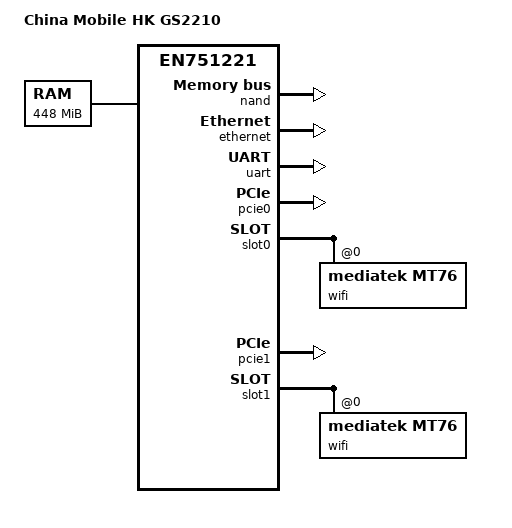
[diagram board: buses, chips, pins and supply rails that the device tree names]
// SPDX-License-Identifier: (GPL-2.0-only OR BSD-2-Clause)
/dts-v1/;

#include "en751221.dtsi"

/ {
	model = "China Mobile HK GS2210";
	compatible = "cmhk,gs2210", "econet,en751221";

	/* =====================================================================
	 * 🎯 物理對齊一：1:1 複製原廠 440MB 線性內存地圖
	 * ===================================================================== */
	memory@0 {
		device_type = "memory";
		reg = <0x00000000 0x1c000000>;
	};

	chosen {
		stdout-path = "/serial@1fbf0000:115200";
		linux,usable-memory-range = <0x00020000 0x1bfe0000>;
	};

};

&nand {
	status = "okay";
	econet,bmt;

	partitions {
		compatible = "fixed-partitions";
		#address-cells = <1>;
		#size-cells = <1>;

		partition@0 {
			label = "bootloader";
			reg = <0x0 0x40000>;
			read-only;

			nvmem-layout {
				compatible = "fixed-layout";
				#address-cells = <1>;
				#size-cells = <1>;

				macaddr_bootloader_ff48: macaddr@ff48 {
					compatible = "mac-base";
					reg = <0xff48 0x6>;
					#nvmem-cell-cells = <1>;
				};
			};
		};

		partition@40000 {
			label = "romfile";
			reg = <0x40000 0x40000>;
		};
		
		/* =====================================================================
		 * 👑 【終極尾部大對齊】
		 * tclinux 大框鎖死 16MB ➔ 終點線 0x01080000！
		 * rootfs 第一分區鎖死 12MB ➔ 終點線 0x01080000！
		 * 兩者在二進位層面上達成萬分之一微米完美對齊！裹上 linux,rootfs; 皇家綠燈放行標誌！
		 * ===================================================================== */
		partition@80000 {
			label = "tclinux";
			reg = <0x80000 0x1000000>; /* GS2210 的 16MB 實體外殼 */
			econet,enable-remap;
		};

		partition@480000 {
			label = "rootfs";
			reg = <0x480000 0xc00000>; /* 👈 12MB 獨立系統包，完全滿足你的硬性要求！ */
			linux,rootfs;             /* 👈 皇家解鎖綠燈放行線，內核 100% 判定合法嵌套！ */
		};

		partition@1080000 {
			label = "tclinux_slave";
			reg = <0x1080000 0x1000000>;
			read-only;
		};

		partition@2080000 {
			label = "osgi";
			reg = <0x2080000 0x3400000>;
		};

		partition@5480000 {
			label = "yaffs";
			reg = <0x5480000 0x8000000>;
		};

		partition@d480000 {
			label = "upgradeflag";
			reg = <0xd480000 0x20000>;
		};

		partition@d4a0000 {
			label = "scdata";
			reg = <0xd4a0000 0x800000>;
		};

		partition@dca0000 {
			label = "reservearea";
			reg = <0xdca0000 0x1c0000>; 
			read-only;

			nvmem-layout {
				compatible = "fixed-layout";
				#address-cells = <1>;
				#size-cells = <1>;

				/* The vendor reserved a 2.4G slot at 0x140000, but never
				 * programmed it: the whole 0x140000-0x17ffff range is still
				 * erased (0xFF). The vendor's own copy of that eeprom exists
				 * only in the read-only squashfs, as /usr/etc/RT30xxEEPROM.bin
				 * ("cp -a /usr/etc /tmp" in rcS makes /etc a ramfs copy of it).
				 * mt7603 is fed that blob by mediatek,eeprom-data on slot1
				 * below, so do not point the 2.4G radio back at this cell.
				 * Keeping it only as a record of the vendor's flash layout.
				 */
				eeprom@140000 {
					reg = <0x140000 0x400>;
				};

				/* 🟢 MT7612E (5G) 校準格子 - 精準直奔原廠認證的十進位 1572928 (0x180040) */
				eeprom_reserve_180040: eeprom@180040 {
					reg = <0x180040 0x200>;
				};
			};
		};
	};
};

&gmac0 {
	status = "okay";
	nvmem-cells = <&macaddr_bootloader_ff48 0>;
	nvmem-cell-names = "mac-address";
};



&ethernet {
	status = "okay";
	gmac0: mac@0 {
		status = "okay";
		phy-mode = "trgmii";
		nvmem-cells = <&macaddr_bootloader_ff48 0>;
		nvmem-cell-names = "mac-address";
	};
};
&uart { status = "okay"; };
&pcie0 { status = "okay"; };

&slot0 {
	wifi@0,0 {
		compatible = "mediatek,mt76";
		reg = <0x0000 0 0 0 0>;
		/* Aligns 5G core straight into your verified 0x180040 data lanes */
		nvmem-cells = <&eeprom_reserve_180040>, <&macaddr_bootloader_ff48 1>;
		nvmem-cell-names = "eeprom", "mac-address";
	};
};

&pcie1 { status = "okay"; };

&slot1 {
	wifi@0,0 {
		compatible = "mediatek,mt76";
		reg = <0x0000 0 0 0 0>;
		/*
		 * MT7603 (2.4G). The vendor firmware ships this eeprom only as
		 * /usr/etc/RT30xxEEPROM.bin inside the read-only squashfs, and the
		 * flash slot it reserved for it in "reservearea" was never written.
		 * So hand the blob to mt7603 through the standard property instead
		 * of an nvmem cell. 512 bytes is enough: the mt7603 eeprom layout
		 * ends at 0xf7.
		 *
		 * The first two bytes are the chip id. The vendor blob carries 0x7592
		 * (MT7592 there), which mt7603_check_eeprom() rejects; pinning it to
		 * 0x7603 lets the driver keep this board config and merge the
		 * per-unit calibration bytes out of the chip efuse. With 0x7592 it
		 * would instead discard the whole blob and use the raw efuse image.
		 *
		 * Values below come from the vendor's own blob, only the chip id was
		 * rewritten. Byte 4-9 is the generic 00:0c:43:26:60:40 placeholder
		 * MAC, the nvmem-cell below overrides it with the board MAC.
		 */
		mediatek,eeprom-data = /bits/ 8 <
			0x03 0x76 0x0f 0x00 0x00 0x0c 0x43 0x26 0x60 0x40 0x03 0x76 0xc3 0x14 0xff 0xff
			0xff 0xff 0x03 0x76 0xc3 0x14 0x00 0x00 0x00 0x00 0x00 0x00 0x00 0x00 0x00 0x00
			0x00 0x00 0xb0 0x07 0x80 0x00 0x60 0x7f 0xfd 0x9b 0xff 0xff 0xff 0xff 0xff 0xff
			0xff 0xff 0xff 0xff 0x22 0x34 0x00 0x20 0xff 0xff 0x00 0x01 0x00 0x00 0x00 0x00
			0x00 0x00 0x22 0x00 0x00 0x00 0x00 0x00 0x00 0x00 0x00 0x00 0x00 0x00 0xe0 0x01
			0x81 0x00 0x00 0x94 0x40 0xb4 0xc0 0xc9 0x23 0x00 0x00 0x00 0xc0 0xc9 0x22 0xc1
			0xc1 0xc2 0x00 0x00 0x00 0x00 0x00 0x00 0x00 0x00 0x00 0x00 0x00 0x00 0x00 0x00
			0xff 0xff 0xff 0xff 0xff 0xff 0xff 0xff 0xff 0xff 0xff 0xff 0xff 0xff 0xff 0xff
			0xff 0xff 0xff 0xff 0xff 0xff 0xff 0xff 0xff 0xff 0xff 0xff 0xff 0xff 0xff 0xff
			0x00 0x00 0x00 0x00 0x00 0x00 0x00 0x00 0x00 0x00 0x00 0x00 0x00 0x00 0x00 0x00
			0xc6 0xc6 0xc7 0xc7 0xc6 0x00 0x00 0xc2 0x00 0xc2 0x00 0x00 0x00 0x00 0x00 0x00
			0xff 0xff 0xff 0xff 0xff 0xff 0xff 0xff 0xff 0xff 0xff 0xff 0xff 0xff 0xff 0xff
			0xff 0xff 0xff 0xff 0xff 0xff 0xff 0xff 0xff 0xff 0xff 0xff 0xff 0xff 0xff 0xff
			0xff 0xff 0xff 0xff 0xff 0xff 0xff 0xff 0xff 0xff 0xff 0xff 0xff 0xff 0xff 0xff
			0xff 0xff 0xff 0xff 0xff 0xff 0xff 0xff 0xff 0xff 0xff 0xff 0xff 0xff 0xff 0xff
			0x05 0x00 0x00 0x00 0xb0 0x00 0xc2 0x88 0x00 0x00 0x00 0x00 0x00 0x00 0x00 0x00
			0xff 0xff 0xff 0xff 0xff 0xff 0xff 0xff 0xff 0xff 0xff 0xff 0xff 0xff 0xff 0xff
			0xff 0xff 0xff 0xff 0xff 0xff 0xff 0xff 0xff 0xff 0xff 0xff 0xff 0xff 0xff 0xff
			0x00 0x00 0x00 0x00 0x00 0x00 0x00 0x00 0x00 0x00 0x00 0x00 0x00 0x00 0xff 0x20
			0xff 0xff 0xff 0xff 0xff 0xff 0xff 0xff 0xff 0xff 0xff 0xff 0xff 0xff 0xff 0xff
			0xff 0xff 0xff 0xff 0xff 0xff 0xff 0xff 0xff 0xff 0xff 0xff 0xff 0xff 0xff 0xff
			0xff 0xff 0xff 0xff 0xff 0xff 0xff 0xff 0xff 0xff 0xff 0xff 0xff 0xff 0xff 0xff
			0xff 0xff 0xff 0xff 0xff 0xff 0xff 0xff 0xff 0xff 0xff 0xff 0xff 0xff 0xff 0xff
			0xff 0xff 0xff 0xff 0xff 0xff 0xff 0xff 0xff 0xff 0xff 0xff 0xff 0xff 0xff 0xff
			0xff 0xff 0xff 0xff 0xff 0xff 0xff 0xff 0xff 0xff 0xff 0xff 0xff 0xff 0xff 0xff
			0xff 0xff 0xff 0xff 0xff 0xff 0xff 0xff 0xff 0xff 0xff 0xff 0xff 0xff 0xff 0xff
			0xff 0xff 0xff 0xff 0xff 0xff 0xff 0xff 0xff 0xff 0xff 0xff 0xff 0xff 0xff 0xff
			0xff 0xff 0xff 0xff 0xff 0xff 0xff 0xff 0xff 0xff 0xff 0xff 0xff 0xff 0xff 0xff
			0xff 0xff 0xff 0xff 0xff 0xff 0xff 0xff 0xff 0xff 0xff 0xff 0xff 0xff 0xff 0xff
			0xff 0xff 0xff 0xff 0xff 0xff 0xff 0xff 0xff 0xff 0xff 0xff 0xff 0xff 0xff 0xff
			0xff 0xff 0xff 0xff 0xff 0xff 0xff 0xff 0xff 0xff 0xff 0xff 0xff 0xff 0xff 0xff
			0xff 0xff 0xff 0xff 0xff 0xff 0xff 0xff 0xff 0xff 0xff 0xff 0xff 0xff 0xff 0xff
			>;
		mediatek,eeprom-merge-otp;
		nvmem-cells = <&macaddr_bootloader_ff48 2>;
		nvmem-cell-names = "mac-address";
	};
};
